# STM32U3C5 register map
File version: 1.0
CPU: CM33 r0p1, little endian, MPU, FPU, 4 interrupt priority bits
Registers are 32-bit, read-write, reset 0x0 unless marked. A register's access mark holds for its fields unless they carry their own. Offsets are from the block's base; [hi:lo] are bit positions; {n}, {i} and the like mark numbered series.

## GTZC1_TZIC — GTZC1_TZIC address block description
Base 0x40032800
Same registers: SEC_GTZC1_TZIC 0x50032800
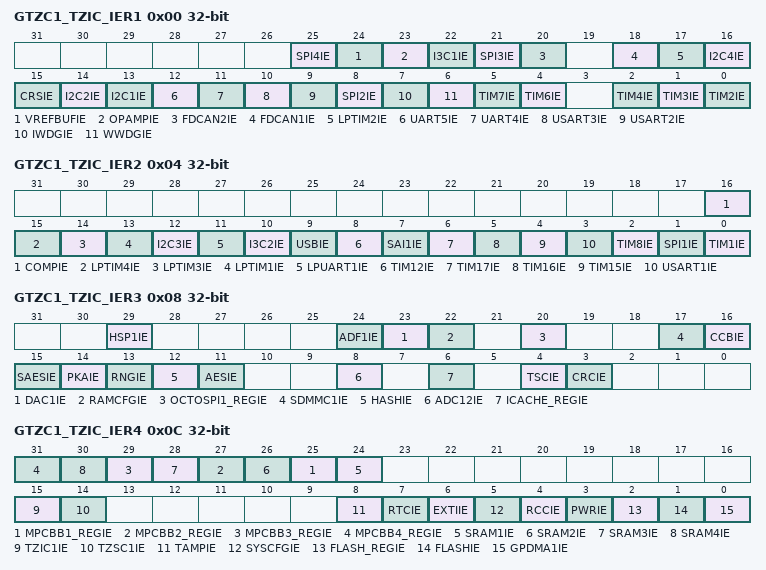
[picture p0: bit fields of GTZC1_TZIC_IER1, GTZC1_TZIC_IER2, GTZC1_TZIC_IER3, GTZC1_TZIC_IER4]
0x00 GTZC1_TZIC_IER1 (alternate view of GTZC1_TZSC_CR) — GTZC1 TZIC interrupt enable register 1
  [all] fields
    0=Interrupt disabled; 1=Interrupt enabled
  [25] SPI4IE — Illegal access interrupt enable for SPI4
  [24] VREFBUFIE — Illegal access interrupt enable for VREFBUF
  [23] OPAMPIE — Illegal access interrupt enable for OPAMP
  [22] I3C1IE — Illegal access interrupt enable for I3C1
  [21] SPI3IE — Illegal access interrupt enable for SPI3
  [20] FDCAN2IE — Illegal access interrupt enable for FDCAN2
  [18] FDCAN1IE — Illegal access interrupt enable for FDCAN1 and FDCAN SRAM
  [17] LPTIM2IE — Illegal access interrupt enable for LPTIM2
  [16] I2C4IE — Illegal access interrupt enable for I2C4
  [15] CRSIE — Illegal access interrupt enable for CRS
  [14] I2C2IE — Illegal access interrupt enable for I2C2
  [13] I2C1IE — Illegal access interrupt enable for I2C1
  [12] UART5IE — Illegal access interrupt enable for UART5
  [11] UART4IE — Illegal access interrupt enable for UART4
  [10] USART3IE — Illegal access interrupt enable for USART3
  [9] USART2IE — Illegal access interrupt enable for USART2
  [8] SPI2IE — Illegal access interrupt enable for SPI2
  [7] IWDGIE — Illegal access interrupt enable for IWDG
  [6] WWDGIE — Illegal access interrupt enable for WWDG
  [5] TIM7IE — Illegal access interrupt enable for TIM7
  [4] TIM6IE — Illegal access interrupt enable for TIM6
  [2] TIM4IE — Illegal access interrupt enable for TIM4
  [1] TIM3IE — Illegal access interrupt enable for TIM3
  [0] TIM2IE — Illegal access interrupt enable for TIM2
0x04 GTZC1_TZIC_IER2 — GTZC1 TZIC interrupt enable register 2
  [all] fields
    0=Interrupt disabled; 1=Interrupt enabled
  [16] COMPIE — Illegal access interrupt enable for COMP
  [15] LPTIM4IE — Illegal access interrupt enable for LPTIM4
  [14] LPTIM3IE — Illegal access interrupt enable for LPTIM3
  [13] LPTIM1IE — Illegal access interrupt enable for LPTIM1
  [12] I2C3IE — Illegal access interrupt enable for I2C3
  [11] LPUART1IE — Illegal access interrupt enable for LPUART1
  [10] I3C2IE — Illegal access interrupt enable for I3C2
  [9] USBIE — Illegal access interrupt enable for USB
  [8] TIM12IE — Illegal access interrupt enable for TIM12
  [7] SAI1IE — Illegal access interrupt enable for SAI1
  [6] TIM17IE — Illegal access interrupt enable for TIM17
  [5] TIM16IE — Illegal access interrupt enable for TIM16
  [4] TIM15IE — Illegal access interrupt enable for TIM15
  [3] USART1IE — Illegal access interrupt enable for USART1
  [2] TIM8IE — Illegal access interrupt enable for TIM8
  [1] SPI1IE — Illegal access interrupt enable for SPI1
  [0] TIM1IE — Illegal access interrupt enable for TIM1
0x08 GTZC1_TZIC_IER3 — GTZC1 TZIC interrupt enable register 3
  [all] fields
    0=Interrupt disabled; 1=Interrupt enabled
  [29] HSP1IE — Illegal access interrupt enable for HSP1
  [24] ADF1IE — Illegal access interrupt enable for ADF1
  [23] DAC1IE — Illegal access interrupt enable for DAC1
  [22] RAMCFGIE — Illegal access interrupt enable for RAMCFG
  [20] OCTOSPI1_REGIE — Illegal access interrupt enable for OCTOSPI1 registers
  [17] SDMMC1IE — Illegal access interrupt enable for SDMMC1
  [16] CCBIE — Illegal access interrupt enable for CCB
  [15] SAESIE — Illegal access interrupt enable for SAES
  [14] PKAIE — Illegal access interrupt enable for PKA
  [13] RNGIE — Illegal access interrupt enable for RNG
  [12] HASHIE — Illegal access interrupt enable for HASH
  [11] AESIE — Illegal access interrupt enable for AES
  [8] ADC12IE — Illegal access interrupt enable for ADC1 and ADC2
  [6] ICACHE_REGIE — Illegal access interrupt enable for ICACHE registers
  [4] TSCIE — Illegal access interrupt enable for TSC
  [3] CRCIE — Illegal access interrupt enable for CRC
0x0C GTZC1_TZIC_IER4 — GTZC1 TZIC interrupt enable register 4
  [2n+23] MPCBB{n}_REGIE (n=1..4) — Illegal access interrupt enable for MPCBB{n} registers
    0=Interrupt disabled; 1=Interrupt enabled
  [2n+22] SRAM{n}IE (n=1..4) — Illegal access interrupt enable for SRAM{n}
    0=Interrupt disabled; 1=Interrupt enabled
  [15] TZIC1IE — Illegal access interrupt enable for GTZC1 TZIC registers
    0=interrupt disabled; 1=interrupt enabled
  [14] TZSC1IE — Illegal access interrupt enable for GTZC1 TZSC registers
    0=Interrupt disabled; 1=Interrupt enabled
  [8] TAMPIE — Illegal access interrupt enable for TAMP
    0=Interrupt disabled; 1=Interrupt enabled
  [7] RTCIE — Illegal access interrupt enable for RTC
    0=Interrupt disabled; 1=Interrupt enabled
  [6] EXTIIE — Illegal access interrupt enable for EXTI
    0=Interrupt disabled; 1=Interrupt enabled
  [5] SYSCFGIE — Illegal access interrupt enable for SYSCFG
    0=Interrupt disabled; 1=Interrupt enabled
  [4] RCCIE — Illegal access interrupt enable for RCC
    0=Interrupt disabled; 1=Interrupt enabled
  [3] PWRIE — Illegal access interrupt enable for PWR
    0=Interrupt disabled; 1=Interrupt enabled
  [2] FLASH_REGIE — Illegal access interrupt enable for FLASH registers
    0=Interrupt disabled; 1=Interrupt enabled
  [1] FLASHIE — Illegal access interrupt enable for FLASH memory
    0=Interrupt disabled; 1=Interrupt enabled
  [0] GPDMA1IE — Illegal access interrupt enable for GPDMA1
    0=Interrupt disabled; 1=Interrupt enabled
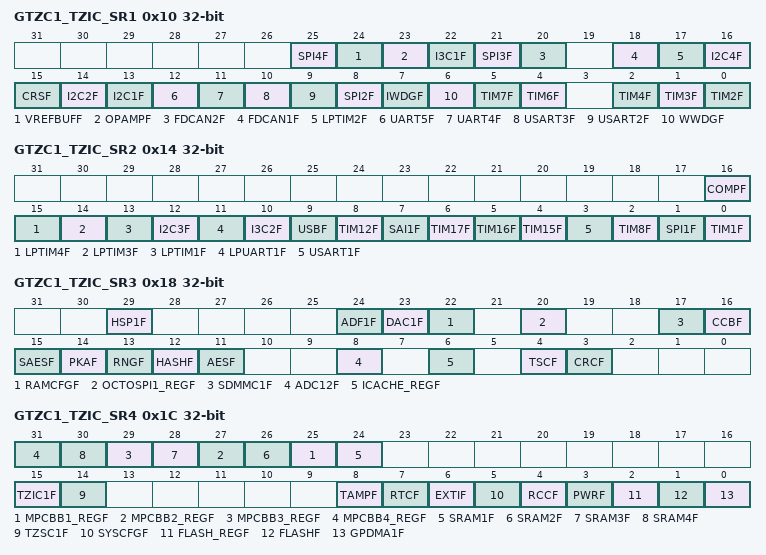
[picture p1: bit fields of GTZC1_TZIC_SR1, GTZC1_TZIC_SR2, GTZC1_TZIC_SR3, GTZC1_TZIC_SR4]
0x10 GTZC1_TZIC_SR1 (alternate view of GTZC1_TZSC_SECCFGR1) — GTZC1 TZIC status register 1
  [all] fields
    0=No illegal access event; 1=Illegal access event
  [25] SPI4F — Illegal access flag for SPI4
  [24] VREFBUFF — Illegal access flag for VREFBUF
  [23] OPAMPF — Illegal access flag for OPAMP
  [22] I3C1F — Illegal access flag for I3C1
  [21] SPI3F — Illegal access flag for SPI3
  [20] FDCAN2F — Illegal access flag for FDCAN2
  [18] FDCAN1F — Illegal access flag for FDCAN1 and FDCAN SRAM
  [17] LPTIM2F — Illegal access flag for LPTIM2
  [16] I2C4F — Illegal access flag for I2C4
  [15] CRSF — Illegal access flag for CRS
  [14] I2C2F — Illegal access flag for I2C2
  [13] I2C1F — Illegal access flag for I2C1
  [12] UART5F — Illegal access flag for UART5
  [11] UART4F — Illegal access flag for UART4
  [10] USART3F — Illegal access flag for USART3
  [9] USART2F — Illegal access flag for USART2
  [8] SPI2F — Illegal access flag for SPI2
  [7] IWDGF — Illegal access flag for IWDG
  [6] WWDGF — Illegal access flag for WWDG
  [5] TIM7F — Illegal access flag for TIM7
  [4] TIM6F — Illegal access flag for TIM6
  [2] TIM4F — Illegal access flag for TIM4
  [1] TIM3F — Illegal access flag for TIM3
  [0] TIM2F — Illegal access flag for TIM2
0x14 GTZC1_TZIC_SR2 (alternate view of GTZC1_TZSC_SECCFGR2) — GTZC1 TZIC status register 2
  [all] fields
    0=No illegal access event; 1=Illegal access event
  [16] COMPF — Illegal access flag for COMP
  [15] LPTIM4F — Illegal access flag for LPTIM4
  [14] LPTIM3F — Illegal access flag for LPTIM3
  [13] LPTIM1F — Illegal access flag for LPTIM1
  [12] I2C3F — Illegal access flag for I2C3
  [11] LPUART1F — Illegal access flag for LPUART1
  [10] I3C2F — Illegal access flag for I3C2
  [9] USBF — Illegal access flag for USB
  [8] TIM12F — Illegal access flag for TIM12
  [7] SAI1F — Illegal access flag for SAI1
  [6] TIM17F — Illegal access flag for TIM17
  [5] TIM16F — Illegal access flag for TIM16
  [4] TIM15F — Illegal access flag for TIM15
  [3] USART1F — Illegal access flag for USART1
  [2] TIM8F — Illegal access flag for TIM8
  [1] SPI1F — Illegal access flag for SPI1
  [0] TIM1F — Illegal access flag for TIM1
0x18 GTZC1_TZIC_SR3 (alternate view of GTZC1_TZSC_SECCFGR3) — GTZC1 TZIC status register 3
  [all] fields
    0=No illegal access event; 1=Illegal access event
  [29] HSP1F — Illegal access flag for HSP1
  [24] ADF1F — Illegal access flag for ADF1
  [23] DAC1F — Illegal access flag for DAC1
  [22] RAMCFGF — Illegal access flag for RAMCFG
  [20] OCTOSPI1_REGF — Illegal access flag for OCTOSPI1 registers
  [17] SDMMC1F — Illegal access flag for SDMMC1
  [16] CCBF — Illegal access flag for CCB
  [15] SAESF — Illegal access flag for SAES
  [14] PKAF — Illegal access flag for PKA
  [13] RNGF — Illegal access flag for RNG
  [12] HASHF — Illegal access flag for HASH
  [11] AESF — Illegal access flag for AES
  [8] ADC12F — Illegal access flag for ADC1 and ADC2
  [6] ICACHE_REGF — Illegal access flag for ICACHE registers
  [4] TSCF — Illegal access flag for TSC
  [3] CRCF — Illegal access flag for CRC
0x1C GTZC1_TZIC_SR4 — GTZC1 TZIC status register 4
  [all] fields
    0=No illegal access event; 1=Illegal access event
  [2n+23] MPCBB{n}_REGF (n=1..4) — Illegal access flag for MPCBB{n} registers
  [2n+22] SRAM{n}F (n=1..4) — Illegal access flag for SRAM{n}
  [15] TZIC1F — Illegal access flag for GTZC1 TZIC registers
  [14] TZSC1F — Illegal access flag for GTZC1 TZSC registers
  [8] TAMPF — Illegal access flag for TAMP
  [7] RTCF — Illegal access flag for RTC
  [6] EXTIF — Illegal access flag for EXTI
  [5] SYSCFGF — Illegal access flag for SYSCFG
  [4] RCCF — Illegal access flag for RCC
  [3] PWRF — Illegal access flag for PWR
  [2] FLASH_REGF — Illegal access flag for FLASH registers
  [1] FLASHF — Illegal access flag for FLASH memory
  [0] GPDMA1F — Illegal access flag for GPDMA1
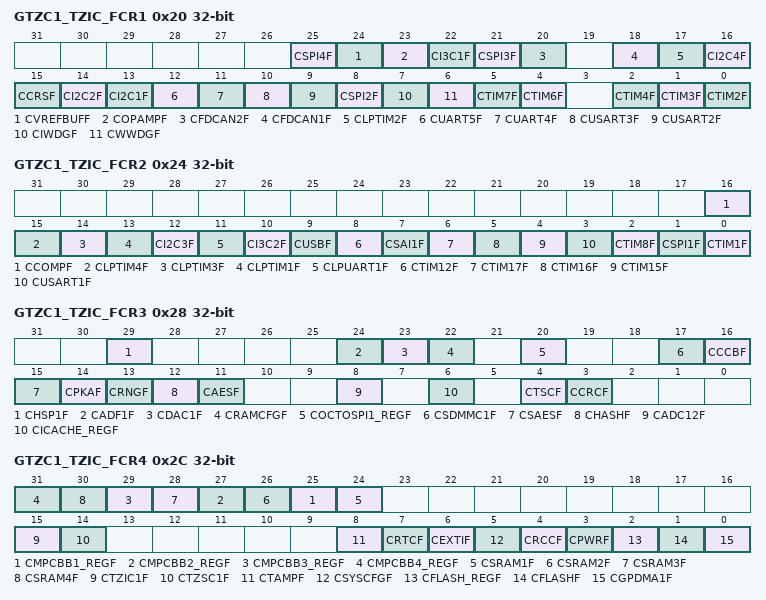
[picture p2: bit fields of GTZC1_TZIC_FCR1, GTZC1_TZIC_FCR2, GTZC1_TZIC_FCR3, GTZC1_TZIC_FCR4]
0x20 GTZC1_TZIC_FCR1 (alternate view of GTZC1_TZSC_PRIVCFGR1) — GTZC1 TZIC flag clear register 1
  [all] fields
    0=No action; 1=Status flag cleared
  [25] CSPI4F — Clear the illegal access flag for SPI4
  [24] CVREFBUFF — Clear the illegal access flag for VREFBUF
  [23] COPAMPF — Clear the illegal access flag for OPAMP
  [22] CI3C1F — Clear the illegal access flag for I3C1
  [21] CSPI3F — Clear the illegal access flag for SPI3
  [20] CFDCAN2F — Clear the illegal access flag for FDCAN2
  [18] CFDCAN1F — Clear the illegal access flag for FDCAN1 and FDCAN SRAM.
  [17] CLPTIM2F — Clear the illegal access flag for LPTIM2
  [16] CI2C4F — Clear the illegal access flag for I2C4
  [15] CCRSF — Clear the illegal access flag for CRS
  [14] CI2C2F — Clear the illegal access flag for I2C2
  [13] CI2C1F — Clear the illegal access flag for I2C1
  [12] CUART5F — Clear the illegal access flag for UART5
  [11] CUART4F — Clear the illegal access flag for UART4
  [10] CUSART3F — Clear the illegal access flag for USART3
  [9] CUSART2F — Clear the illegal access flag for USART2
  [8] CSPI2F — Clear the illegal access flag for SPI2
  [7] CIWDGF — Clear the illegal access flag for IWDG
  [6] CWWDGF — Clear the illegal access flag for WWDG
  [5] CTIM7F — Clear the illegal access flag for TIM7
  [4] CTIM6F — Clear the illegal access flag for TIM6
  [2] CTIM4F — Clear the illegal access flag for TIM4
  [1] CTIM3F — Clear the illegal access flag for TIM3
  [0] CTIM2F — Clear the illegal access flag for TIM2
0x24 GTZC1_TZIC_FCR2 (alternate view of GTZC1_TZSC_PRIVCFGR2) — GTZC1 TZIC flag clear register 2
  [all] fields
    0=No action; 1=Status flag cleared
  [16] CCOMPF — Clear the illegal access flag for COMP
  [15] CLPTIM4F — Clear the illegal access flag for LPTIM4
  [14] CLPTIM3F — Clear the illegal access flag for LPTIM3
  [13] CLPTIM1F — Clear the illegal access flag for LPTIM1
  [12] CI2C3F — Clear the illegal access flag for I2C3
  [11] CLPUART1F — Clear the illegal access flag for LPUART1
  [10] CI3C2F — Clear the illegal access flag for I3C2
  [9] CUSBF — Clear the illegal access flag for USB
  [8] CTIM12F — Clear the illegal access flag for TIM12
  [7] CSAI1F — Clear the illegal access flag for SAI1
  [6] CTIM17F — Clear the illegal access flag for TIM17
  [5] CTIM16F — Clear the illegal access flag for TIM16
  [4] CTIM15F — Clear the illegal access flag for TIM15
  [3] CUSART1F — Clear the illegal access flag for USART1
  [2] CTIM8F — Clear the illegal access flag for TIM8
  [1] CSPI1F — Clear the illegal access flag for SPI1
  [0] CTIM1F — Clear the illegal access flag for TIM1
0x28 GTZC1_TZIC_FCR3 (alternate view of GTZC1_TZSC_PRIVCFGR3) — GTZC1 TZIC flag clear register 3
  [all] fields
    0=No action; 1=Status flag cleared
  [29] CHSP1F — Clear the illegal access flag for HSP1
  [24] CADF1F — Clear the illegal access flag for ADF1
  [23] CDAC1F — Clear the illegal access flag for DAC1
  [22] CRAMCFGF — Clear the illegal access flag for RAMCFG
  [20] COCTOSPI1_REGF — Clear the illegal access flag for OCTOSPI1 registers
  [17] CSDMMC1F — Clear the illegal access flag for SDMMC1
  [16] CCCBF — Clear the illegal access flag for CCB
  [15] CSAESF — Clear the illegal access flag for SAES
  [14] CPKAF — Clear the illegal access flag for PKA
  [13] CRNGF — Clear the illegal access flag for RNG
  [12] CHASHF — Clear the illegal access flag for HASH
  [11] CAESF — Clear the illegal access flag for AES
  [8] CADC12F — Clear the illegal access flag for ADC1 and ADC2
  [6] CICACHE_REGF — Clear the illegal access flag for ICACHE registers
  [4] CTSCF — Clear the illegal access flag for TSC
  [3] CCRCF — Clear the illegal access flag for CRC
0x2C GTZC1_TZIC_FCR4 — GTZC1 TZIC flag clear register 4
  [all] fields
    0=No action; 1=Status flag cleared
  [2n+23] CMPCBB{n}_REGF (n=1..4) — Clear the illegal access flag for MPCBB{n} registers
  [2n+22] CSRAM{n}F (n=1..4) — Clear the illegal access flag for SRAM{n}
  [15] CTZIC1F — Clear the illegal access flag for GTZC1 TZIC registers
  [14] CTZSC1F — Clear the illegal access flag for GTZC1 TZSC registers
  [8] CTAMPF — Clear the illegal access flag for TAMP
  [7] CRTCF — Clear the illegal access flag for RTC
  [6] CEXTIF — Clear the illegal access flag for EXTI
  [5] CSYSCFGF — Clear the illegal access flag for SYSCFG
  [4] CRCCF — Clear the illegal access flag for RCC
  [3] CPWRF — Clear the illegal access flag for PWR
  [2] CFLASH_REGF — Clear the illegal access flag for FLASH registers
  [1] CFLASHF — Clear the illegal access flag for FLASH memory
  [0] CGPDMA1F — Clear the illegal access flag for GPDMA1
